AUTOSAR XML (schema 4-3-0)
package /ComponentTypes
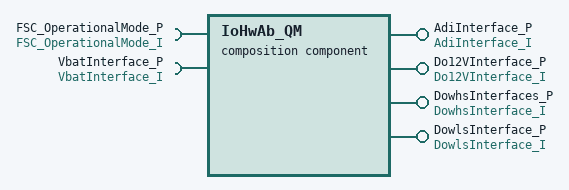
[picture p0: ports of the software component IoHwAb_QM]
  composition sw component type IoHwAb_QM
    4 x provide port:
      AdiInterface_P: provided-interface=AdiInterface_I
      Do12VInterface_P: provided-interface=Do12VInterface_I
      DowhsInterfaces_P: provided-interface=DowhsInterface_I
      DowlsInterface_P: provided-interface=DowlsInterface_I
    require port FSC_OperationalMode_P: required-com-specs=[FSC_OperationalMode, VbatInterface_P], required-interface=FSC_OperationalMode_I
    require port VbatInterface_P: required-interface=VbatInterface_I
      required-com-specs:
        DobhsCtrlInterface_P_4
        DobhsCtrlInterface_P_5
        DobhsCtrlInterface_P_3
        DobhsCtrlInterface_P_2
        DobhsCtrlInterface_P_1
        FSC_OperationalMode
        VbatInterface_P
    component IoHwAb_QM_Radio: type=IoHwAb_QM_Radio
    component IoHwAb_QM_IO: type=IoHwAb_QM_IO
    delegate IoHwAb_QM_IO.VbatInterface_P <-> outer port VbatInterface_P
    delegate IoHwAb_QM_IO.FSC_OperationalMode_P <-> outer port FSC_OperationalMode_P
    delegate IoHwAb_QM_Radio.VbatInterface_P <-> outer port VbatInterface_P
    delegate IoHwAb_QM_IO.AdiInterface_P <-> outer port AdiInterface_P
    delegate IoHwAb_QM_IO.DowhsInterfaces_P <-> outer port DowlsInterface_P
    delegate IoHwAb_QM_IO.Do12VInterface_P <-> outer port Do12VInterface_P
    delegate IoHwAb_QM_IO.DowlsInterface_P <-> outer port DowhsInterfaces_P
    delegate IoHwAb_QM_Radio.FSC_OperationalMode_P <-> outer port FSC_OperationalMode_P
